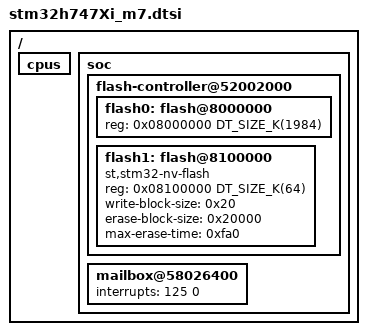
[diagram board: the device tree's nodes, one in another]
/*
 * Copyright (c) 2019 Linaro Limited
 *
 * SPDX-License-Identifier: Apache-2.0
 */

#include <mem.h>
#include <st/h7/stm32h747.dtsi>



/ {
	cpus {
		/delete-node/ cpu@1;
	};

	soc {
		flash-controller@52002000 {
			flash0: flash@8000000 {
				reg = <0x08000000 DT_SIZE_K(1984)>;
			};
			flash1: flash@8100000 {  
				reg = <0x08100000 DT_SIZE_K(64)>; 
				compatible = "st,stm32-nv-flash", "soc-nv-flash"; 
				write-block-size = < 0x20 >; 
				erase-block-size = < 0x20000 >; 
				max-erase-time = < 0xfa0 >;  
			};
		};

		mailbox@58026400 {
			interrupts = <125 0>;
		};
	};
};
